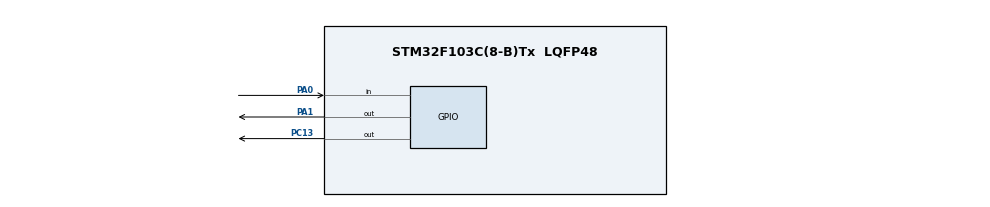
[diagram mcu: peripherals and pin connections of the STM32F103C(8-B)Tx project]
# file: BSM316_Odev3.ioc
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Mcu.Family=STM32F1
Mcu.Name=STM32F103C(8-B)Tx
Mcu.Package=LQFP48
NVIC.PriorityGroup=NVIC_PRIORITYGROUP_4
NVIC.TIM2_IRQn=true\:0\:0\:false\:false\:true\:true\:true\:true
PA0-WKUP.GPIO_PuPd=GPIO_PULLUP
PA0-WKUP.Signal=GPIO_Input
PA1.Signal=GPIO_Output
PA13.Mode=Serial_Wire
PA13.Signal=SYS_JTMS-SWDIO
PA14.Mode=Serial_Wire
PA14.Signal=SYS_JTCK-SWCLK
PC13-TAMPER-RTC.Signal=GPIO_Output
PD0-OSC_IN.Mode=HSE-External-Oscillator
PD0-OSC_IN.Signal=RCC_OSC_IN
PD1-OSC_OUT.Mode=HSE-External-Oscillator
PD1-OSC_OUT.Signal=RCC_OSC_OUT
ProjectManager.HeapSize=0x200
ProjectManager.StackSize=0x400
ProjectManager.TargetToolchain=CMake
RCC.APB1Freq_Value=8000000
RCC.APB2Freq_Value=8000000
TIM2.Period=999
TIM2.Prescaler=7999
VP_TIM2_VS_ClockSourceINT.Mode=Internal
board=custom

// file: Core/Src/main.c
/* USER CODE BEGIN Header */
/**
  ******************************************************************************
  * @file           : main.c
  * @brief          : Main program body
  ******************************************************************************
  * @attention
  *
  * Copyright (c) 2026 STMicroelectronics.
  * All rights reserved.
  *
  * This software is licensed under terms that can be found in the LICENSE file
  * in the root directory of this software component.
  * If no LICENSE file comes with this software, it is provided AS-IS.
  *
  ******************************************************************************
  */
/* USER CODE END Header */
#include "main.h"

TIM_HandleTypeDef htim2;

/* USER CODE BEGIN PV */
uint16_t blink_count = 4;
volatile uint16_t current_blinks = 0;
volatile uint8_t wait_seconds = 0;
volatile uint8_t is_waiting = 0;
volatile uint8_t led_is_on = 0;
/* USER CODE END PV */

void SystemClock_Config(void);
static void MX_GPIO_Init(void);
static void MX_TIM2_Init(void);

/* USER CODE BEGIN 0 */
#define FLASH_STORAGE_ADDR 0x0800FC00

void Save_To_Flash(uint16_t data) {
    HAL_FLASH_Unlock();

    FLASH_EraseInitTypeDef EraseInitStruct;
    uint32_t PageError = 0;

    EraseInitStruct.TypeErase = FLASH_TYPEERASE_PAGES;
    EraseInitStruct.PageAddress = FLASH_STORAGE_ADDR;
    EraseInitStruct.NbPages = 1;

    if (HAL_FLASHEx_Erase(&EraseInitStruct, &PageError) == HAL_OK) {
        HAL_FLASH_Program(FLASH_TYPEPROGRAM_HALFWORD, FLASH_STORAGE_ADDR, data);
    }

    HAL_FLASH_Lock();
}

uint16_t Read_From_Flash(void) {
    return *(__IO uint16_t *)FLASH_STORAGE_ADDR;
}
/* USER CODE END 0 */

int main(void)
{

  /* MCU Configuration--------------------------------------------------------*/

  /* Reset of all peripherals, Initializes the Flash interface and the Systick. */
  HAL_Init();

  /* Configure the system clock */
  SystemClock_Config();

  /* Initialize all configured peripherals */
  MX_GPIO_Init();
  MX_TIM2_Init();
  /* USER CODE BEGIN 2 */
  HAL_GPIO_WritePin(GPIOC, GPIO_PIN_13, GPIO_PIN_SET);

  uint16_t flash_val = Read_From_Flash();

  if(flash_val > 7 || flash_val < 4) {
      blink_count = 4;
      Save_To_Flash(blink_count);
  } else {
      blink_count = flash_val;
  }

  HAL_TIM_Base_Start_IT(&htim2);

  uint8_t last_btn_state = GPIO_PIN_SET;
  uint32_t press_start_time = 0;

  //Kart açıldığı an buton basıyor mu kontrolü
  uint8_t startup_button_held = 0;
  if (HAL_GPIO_ReadPin(GPIOA, GPIO_PIN_0) == GPIO_PIN_RESET) {
      startup_button_held = 1;
  }
  /* USER CODE END 2 */

  /* Infinite loop */
  /* USER CODE BEGIN WHILE */
  while (1)
  {
    uint8_t current_btn_state = HAL_GPIO_ReadPin(GPIOA, GPIO_PIN_0);

      // Kart açıldığından itibaren basılı tutulma durumu (Fabrika Ayarı)
      if (startup_button_held) {
          if (current_btn_state == GPIO_PIN_SET) {
              // 3 saniye dolmadan buton bırakılırsa işlemi iptal et
              startup_button_held = 0;
          } else if (HAL_GetTick() >= 3000) {
              // Kart açıldığından beri 3 saniye geçti ve buton bırakılmadıysa
              blink_count = 4; // Değeri varsayılan fabrika ayarına eşitle
              Save_To_Flash(blink_count); // Yeni değeri kalıcı hafızaya kaydet
              startup_button_held = 0; // Sıfırlama yapıldı
          }
      }
      // Normal Çalışma Modu
      else {
          if (current_btn_state == GPIO_PIN_RESET && last_btn_state == GPIO_PIN_SET) {
              press_start_time = HAL_GetTick(); // Basılma anını kaydet
          }
          else if (current_btn_state == GPIO_PIN_SET && last_btn_state == GPIO_PIN_RESET) {
              // press_start_time 0'dan farklıysa artır
              // (HAL_GetTick() - press_start_time > 50): mekanik titremelerini peş peşe basılma olarak algılamaması için 50 ms bekleme
              if (press_start_time != 0 && (HAL_GetTick() - press_start_time > 50)) {
                  blink_count++;
                  if (blink_count > 7) blink_count = 4; // Değer 7'yi geçerse tekrar 4'e döndür
                  Save_To_Flash(blink_count); // Güncellenmiş sayıyı, enerji kesilse bile hatırlaması için Flash hafızaya yaz
              }
              press_start_time = 0; // İşlem bitti bir sonraki basış için sıfırla
          }
      }

      last_btn_state = current_btn_state;
    /* USER CODE END WHILE */

  }
}

void SystemClock_Config(void)
{
  RCC_OscInitTypeDef RCC_OscInitStruct = {0};
  RCC_ClkInitTypeDef RCC_ClkInitStruct = {0};

  /** Initializes the RCC Oscillators according to the specified parameters
  * in the RCC_OscInitTypeDef structure.
  */
  RCC_OscInitStruct.OscillatorType = RCC_OSCILLATORTYPE_HSI;
  RCC_OscInitStruct.HSIState = RCC_HSI_ON;
  RCC_OscInitStruct.HSICalibrationValue = RCC_HSICALIBRATION_DEFAULT;
  RCC_OscInitStruct.PLL.PLLState = RCC_PLL_NONE;
  if (HAL_RCC_OscConfig(&RCC_OscInitStruct) != HAL_OK)
  {
    Error_Handler();
  }

  /** Initializes the CPU, AHB and APB buses clocks
  */
  RCC_ClkInitStruct.ClockType = RCC_CLOCKTYPE_HCLK|RCC_CLOCKTYPE_SYSCLK
                              |RCC_CLOCKTYPE_PCLK1|RCC_CLOCKTYPE_PCLK2;
  RCC_ClkInitStruct.SYSCLKSource = RCC_SYSCLKSOURCE_HSI;
  RCC_ClkInitStruct.AHBCLKDivider = RCC_SYSCLK_DIV1;
  RCC_ClkInitStruct.APB1CLKDivider = RCC_HCLK_DIV1;
  RCC_ClkInitStruct.APB2CLKDivider = RCC_HCLK_DIV1;

  if (HAL_RCC_ClockConfig(&RCC_ClkInitStruct, FLASH_LATENCY_0) != HAL_OK)
  {
    Error_Handler();
  }
}

static void MX_TIM2_Init(void)
{

  TIM_ClockConfigTypeDef sClockSourceConfig = {0};
  TIM_MasterConfigTypeDef sMasterConfig = {0};

  htim2.Instance = TIM2;
  htim2.Init.Prescaler = 7999;
  htim2.Init.CounterMode = TIM_COUNTERMODE_UP;
  htim2.Init.Period = 999;
  htim2.Init.ClockDivision = TIM_CLOCKDIVISION_DIV1;
  htim2.Init.AutoReloadPreload = TIM_AUTORELOAD_PRELOAD_DISABLE;
  if (HAL_TIM_Base_Init(&htim2) != HAL_OK)
  {
    Error_Handler();
  }
  sClockSourceConfig.ClockSource = TIM_CLOCKSOURCE_INTERNAL;
  if (HAL_TIM_ConfigClockSource(&htim2, &sClockSourceConfig) != HAL_OK)
  {
    Error_Handler();
  }
  sMasterConfig.MasterOutputTrigger = TIM_TRGO_RESET;
  sMasterConfig.MasterSlaveMode = TIM_MASTERSLAVEMODE_DISABLE;
  if (HAL_TIMEx_MasterConfigSynchronization(&htim2, &sMasterConfig) != HAL_OK)
  {
    Error_Handler();
  }

}

static void MX_GPIO_Init(void)
{
  GPIO_InitTypeDef GPIO_InitStruct = {0};

  /* GPIO Ports Clock Enable */
  __HAL_RCC_GPIOC_CLK_ENABLE();
  __HAL_RCC_GPIOD_CLK_ENABLE();
  __HAL_RCC_GPIOA_CLK_ENABLE();

  /*Configure GPIO pin Output Level */
  HAL_GPIO_WritePin(GPIOC, GPIO_PIN_13, GPIO_PIN_RESET);

  /*Configure GPIO pin Output Level */
  HAL_GPIO_WritePin(GPIOA, GPIO_PIN_1, GPIO_PIN_RESET);

  /*Configure GPIO pin : PC13 */
  GPIO_InitStruct.Pin = GPIO_PIN_13;
  GPIO_InitStruct.Mode = GPIO_MODE_OUTPUT_PP;
  GPIO_InitStruct.Pull = GPIO_NOPULL;
  GPIO_InitStruct.Speed = GPIO_SPEED_FREQ_LOW;
  HAL_GPIO_Init(GPIOC, &GPIO_InitStruct);

  /*Configure GPIO pin : PA0 */
  GPIO_InitStruct.Pin = GPIO_PIN_0;
  GPIO_InitStruct.Mode = GPIO_MODE_INPUT;
  GPIO_InitStruct.Pull = GPIO_PULLUP;
  HAL_GPIO_Init(GPIOA, &GPIO_InitStruct);

  /*Configure GPIO pin : PA1 */
  GPIO_InitStruct.Pin = GPIO_PIN_1;
  GPIO_InitStruct.Mode = GPIO_MODE_OUTPUT_PP;
  GPIO_InitStruct.Pull = GPIO_NOPULL;
  GPIO_InitStruct.Speed = GPIO_SPEED_FREQ_LOW;
  HAL_GPIO_Init(GPIOA, &GPIO_InitStruct);

}

/* USER CODE BEGIN 4 */
void HAL_TIM_PeriodElapsedCallback(TIM_HandleTypeDef *htim)
{
    if (htim->Instance == TIM2)
    {
        if (is_waiting) {
            wait_seconds++;
            if (wait_seconds >= 5) {
                is_waiting = 0;
                wait_seconds = 0;
                current_blinks = 0;
            }
        }
        else {
            if (led_is_on) {
                HAL_GPIO_WritePin(GPIOC, GPIO_PIN_13, GPIO_PIN_SET); // LEd söndü
                led_is_on = 0;
                current_blinks++; // Bir tam yanma-sonme dongusu tamamlandi

                if (current_blinks >= blink_count) {
                    is_waiting = 1;
                }
            } else {
                HAL_GPIO_WritePin(GPIOC, GPIO_PIN_13, GPIO_PIN_RESET); // Led yandı
                led_is_on = 1;
            }
        }
    }
}
/* USER CODE END 4 */

void Error_Handler(void)
{
  __disable_irq();
  while (1)
  {
  }
}
